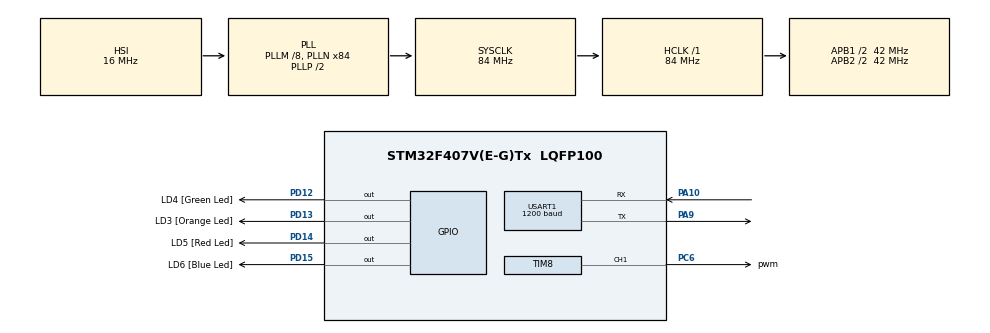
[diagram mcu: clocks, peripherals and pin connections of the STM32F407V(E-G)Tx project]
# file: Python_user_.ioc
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Mcu.Family=STM32F4
Mcu.Name=STM32F407V(E-G)Tx
Mcu.Package=LQFP100
NVIC.PriorityGroup=NVIC_PRIORITYGROUP_0
NVIC.USART1_IRQn=true\:0\:0\:false\:false\:true\:true\:true\:true
PA10.Mode=Asynchronous
PA10.Signal=USART1_RX
PA9.Mode=Asynchronous
PA9.Signal=USART1_TX
PC6.GPIO_Label=pwm
PC6.Signal=S_TIM8_CH1
PD12.GPIO_Label=LD4 [Green Led]
PD12.GPIO_PuPd=GPIO_NOPULL
PD12.GPIO_Speed=GPIO_SPEED_FREQ_LOW
PD12.Signal=GPIO_Output
PD13.GPIO_Label=LD3 [Orange Led]
PD13.GPIO_PuPd=GPIO_NOPULL
PD13.GPIO_Speed=GPIO_SPEED_FREQ_LOW
PD13.Signal=GPIO_Output
PD14.GPIO_Label=LD5 [Red Led]
PD14.GPIO_PuPd=GPIO_NOPULL
PD14.GPIO_Speed=GPIO_SPEED_FREQ_LOW
PD14.Signal=GPIO_Output
PD15.GPIO_Label=LD6 [Blue Led]
PD15.GPIO_PuPd=GPIO_NOPULL
PD15.GPIO_Speed=GPIO_SPEED_FREQ_LOW
PD15.Signal=GPIO_Output
ProjectManager.HeapSize=0x200
ProjectManager.StackSize=0x400
ProjectManager.TargetToolchain=STM32CubeIDE
RCC.48MHZClocksFreq_Value=24000000
RCC.AHBFreq_Value=84000000
RCC.APB1CLKDivider=RCC_HCLK_DIV2
RCC.APB1Freq_Value=42000000
RCC.APB1TimFreq_Value=84000000
RCC.APB2CLKDivider=RCC_HCLK_DIV2
RCC.APB2Freq_Value=42000000
RCC.APB2TimFreq_Value=84000000
RCC.CortexFreq_Value=84000000
RCC.HCLKFreq_Value=84000000
RCC.HSE_VALUE=8000000
RCC.HSI_VALUE=16000000
RCC.LSE_VALUE=32768
RCC.PLLM=8
RCC.PLLN=84
RCC.PLLQ=7
RCC.SYSCLKFreq_VALUE=84000000
RCC.SYSCLKSource=RCC_SYSCLKSOURCE_PLLCLK
RCC.VCOOutputFreq_Value=168000000
SH.S_TIM8_CH1.0=TIM8_CH1,PWM Generation1 CH1
TIM1.Period=65535-1
TIM1.Prescaler=839
TIM8.AutoReloadPreload=TIM_AUTORELOAD_PRELOAD_ENABLE
TIM8.Channel-PWM\ Generation1\ CH1=TIM_CHANNEL_1
TIM8.Period=9999
TIM8.Prescaler=167
USART1.BaudRate=1200
USART1.VirtualMode=VM_ASYNC
VP_TIM1_VS_ClockSourceINT.Mode=Internal
VP_TIM8_VS_ClockSourceINT.Mode=Internal
board=STM32F407G-DISC1

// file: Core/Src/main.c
/* USER CODE BEGIN Header */
/**
  ******************************************************************************
  * @file           : main.c
  * @brief          : Main program body
  ******************************************************************************
  * @attention
  *
  * Copyright (c) 2022 STMicroelectronics.
  * All rights reserved.
  *
  * This software is licensed under terms that can be found in the LICENSE file
  * in the root directory of this software component.
  * If no LICENSE file comes with this software, it is provided AS-IS.
  *
  ******************************************************************************
  */
/* USER CODE END Header */
#include "main.h"
#include "led_driver.h"
#include "string.h"

TIM_HandleTypeDef htim1;
TIM_HandleTypeDef htim8;

UART_HandleTypeDef huart1;

void SystemClock_Config(void);
static void MX_GPIO_Init(void);
static void MX_TIM8_Init(void);
static void MX_USART1_UART_Init(void);
static void MX_TIM1_Init(void);
/* USER CODE BEGIN PFP */
void Pyqt_led_app(uint8_t *data);
/* USER CODE END PFP */

/* USER CODE BEGIN 0 */
uint8_t gdata[3];

/* USER CODE END 0 */

int main(void)
{

  /* MCU Configuration--------------------------------------------------------*/

  /* Reset of all peripherals, Initializes the Flash interface and the Systick. */
  HAL_Init();

  /* Configure the system clock */
  SystemClock_Config();

  /* Initialize all configured peripherals */
  MX_GPIO_Init();
  MX_TIM8_Init();
  MX_USART1_UART_Init();
  MX_TIM1_Init();
  /* USER CODE BEGIN 2 */

HAL_UART_Receive_IT(&huart1, (uint8_t*)gdata,2);

HAL_TIM_PWM_Start(&htim8,TIM_CHANNEL_1);

  /* USER CODE END 2 */

  /* Infinite loop */
  /* USER CODE BEGIN WHILE */
  while (1)
  {

	  LED_Apps(gdata);                               //

	 HAL_UART_Receive_IT(&huart1,(uint8_t*)gdata,2); //

    /* USER CODE END WHILE */

  }
}

void SystemClock_Config(void)
{
  RCC_OscInitTypeDef RCC_OscInitStruct = {0};
  RCC_ClkInitTypeDef RCC_ClkInitStruct = {0};

  /** Configure the main internal regulator output voltage
  */
  __HAL_RCC_PWR_CLK_ENABLE();
  __HAL_PWR_VOLTAGESCALING_CONFIG(PWR_REGULATOR_VOLTAGE_SCALE1);

  /** Initializes the RCC Oscillators according to the specified parameters
  * in the RCC_OscInitTypeDef structure.
  */
  RCC_OscInitStruct.OscillatorType = RCC_OSCILLATORTYPE_HSI;
  RCC_OscInitStruct.HSIState = RCC_HSI_ON;
  RCC_OscInitStruct.HSICalibrationValue = RCC_HSICALIBRATION_DEFAULT;
  RCC_OscInitStruct.PLL.PLLState = RCC_PLL_ON;
  RCC_OscInitStruct.PLL.PLLSource = RCC_PLLSOURCE_HSI;
  RCC_OscInitStruct.PLL.PLLM = 8;
  RCC_OscInitStruct.PLL.PLLN = 84;
  RCC_OscInitStruct.PLL.PLLP = RCC_PLLP_DIV2;
  RCC_OscInitStruct.PLL.PLLQ = 7;
  if (HAL_RCC_OscConfig(&RCC_OscInitStruct) != HAL_OK)
  {
    Error_Handler();
  }

  /** Initializes the CPU, AHB and APB buses clocks
  */
  RCC_ClkInitStruct.ClockType = RCC_CLOCKTYPE_HCLK|RCC_CLOCKTYPE_SYSCLK
                              |RCC_CLOCKTYPE_PCLK1|RCC_CLOCKTYPE_PCLK2;
  RCC_ClkInitStruct.SYSCLKSource = RCC_SYSCLKSOURCE_PLLCLK;
  RCC_ClkInitStruct.AHBCLKDivider = RCC_SYSCLK_DIV1;
  RCC_ClkInitStruct.APB1CLKDivider = RCC_HCLK_DIV2;
  RCC_ClkInitStruct.APB2CLKDivider = RCC_HCLK_DIV2;

  if (HAL_RCC_ClockConfig(&RCC_ClkInitStruct, FLASH_LATENCY_2) != HAL_OK)
  {
    Error_Handler();
  }
}

static void MX_TIM1_Init(void)
{

  TIM_ClockConfigTypeDef sClockSourceConfig = {0};
  TIM_MasterConfigTypeDef sMasterConfig = {0};

  htim1.Instance = TIM1;
  htim1.Init.Prescaler = 839;
  htim1.Init.CounterMode = TIM_COUNTERMODE_UP;
  htim1.Init.Period = 65535-1;
  htim1.Init.ClockDivision = TIM_CLOCKDIVISION_DIV1;
  htim1.Init.RepetitionCounter = 0;
  htim1.Init.AutoReloadPreload = TIM_AUTORELOAD_PRELOAD_DISABLE;
  if (HAL_TIM_Base_Init(&htim1) != HAL_OK)
  {
    Error_Handler();
  }
  sClockSourceConfig.ClockSource = TIM_CLOCKSOURCE_INTERNAL;
  if (HAL_TIM_ConfigClockSource(&htim1, &sClockSourceConfig) != HAL_OK)
  {
    Error_Handler();
  }
  sMasterConfig.MasterOutputTrigger = TIM_TRGO_RESET;
  sMasterConfig.MasterSlaveMode = TIM_MASTERSLAVEMODE_DISABLE;
  if (HAL_TIMEx_MasterConfigSynchronization(&htim1, &sMasterConfig) != HAL_OK)
  {
    Error_Handler();
  }

}

static void MX_TIM8_Init(void)
{

  TIM_ClockConfigTypeDef sClockSourceConfig = {0};
  TIM_MasterConfigTypeDef sMasterConfig = {0};
  TIM_OC_InitTypeDef sConfigOC = {0};
  TIM_BreakDeadTimeConfigTypeDef sBreakDeadTimeConfig = {0};

  htim8.Instance = TIM8;
  htim8.Init.Prescaler = 167;
  htim8.Init.CounterMode = TIM_COUNTERMODE_UP;
  htim8.Init.Period = 9999;
  htim8.Init.ClockDivision = TIM_CLOCKDIVISION_DIV1;
  htim8.Init.RepetitionCounter = 0;
  htim8.Init.AutoReloadPreload = TIM_AUTORELOAD_PRELOAD_ENABLE;
  if (HAL_TIM_Base_Init(&htim8) != HAL_OK)
  {
    Error_Handler();
  }
  sClockSourceConfig.ClockSource = TIM_CLOCKSOURCE_INTERNAL;
  if (HAL_TIM_ConfigClockSource(&htim8, &sClockSourceConfig) != HAL_OK)
  {
    Error_Handler();
  }
  if (HAL_TIM_PWM_Init(&htim8) != HAL_OK)
  {
    Error_Handler();
  }
  sMasterConfig.MasterOutputTrigger = TIM_TRGO_RESET;
  sMasterConfig.MasterSlaveMode = TIM_MASTERSLAVEMODE_DISABLE;
  if (HAL_TIMEx_MasterConfigSynchronization(&htim8, &sMasterConfig) != HAL_OK)
  {
    Error_Handler();
  }
  sConfigOC.OCMode = TIM_OCMODE_PWM1;
  sConfigOC.Pulse = 0;
  sConfigOC.OCPolarity = TIM_OCPOLARITY_HIGH;
  sConfigOC.OCNPolarity = TIM_OCNPOLARITY_HIGH;
  sConfigOC.OCFastMode = TIM_OCFAST_DISABLE;
  sConfigOC.OCIdleState = TIM_OCIDLESTATE_RESET;
  sConfigOC.OCNIdleState = TIM_OCNIDLESTATE_RESET;
  if (HAL_TIM_PWM_ConfigChannel(&htim8, &sConfigOC, TIM_CHANNEL_1) != HAL_OK)
  {
    Error_Handler();
  }
  sBreakDeadTimeConfig.OffStateRunMode = TIM_OSSR_DISABLE;
  sBreakDeadTimeConfig.OffStateIDLEMode = TIM_OSSI_DISABLE;
  sBreakDeadTimeConfig.LockLevel = TIM_LOCKLEVEL_OFF;
  sBreakDeadTimeConfig.DeadTime = 0;
  sBreakDeadTimeConfig.BreakState = TIM_BREAK_DISABLE;
  sBreakDeadTimeConfig.BreakPolarity = TIM_BREAKPOLARITY_HIGH;
  sBreakDeadTimeConfig.AutomaticOutput = TIM_AUTOMATICOUTPUT_DISABLE;
  if (HAL_TIMEx_ConfigBreakDeadTime(&htim8, &sBreakDeadTimeConfig) != HAL_OK)
  {
    Error_Handler();
  }
  HAL_TIM_MspPostInit(&htim8);

}

static void MX_USART1_UART_Init(void)
{

  huart1.Instance = USART1;
  huart1.Init.BaudRate = 1200;
  huart1.Init.WordLength = UART_WORDLENGTH_8B;
  huart1.Init.StopBits = UART_STOPBITS_1;
  huart1.Init.Parity = UART_PARITY_NONE;
  huart1.Init.Mode = UART_MODE_TX_RX;
  huart1.Init.HwFlowCtl = UART_HWCONTROL_NONE;
  huart1.Init.OverSampling = UART_OVERSAMPLING_16;
  if (HAL_UART_Init(&huart1) != HAL_OK)
  {
    Error_Handler();
  }
  /* USER CODE BEGIN USART1_Init 2 */
  HAL_NVIC_SetPriority(USART1_IRQn  , 0, 0);
  HAL_NVIC_EnableIRQ(USART1_IRQn);
  /* USER CODE END USART1_Init 2 */

}

static void MX_GPIO_Init(void)
{
  GPIO_InitTypeDef GPIO_InitStruct = {0};

  /* GPIO Ports Clock Enable */
  __HAL_RCC_GPIOD_CLK_ENABLE();
  __HAL_RCC_GPIOC_CLK_ENABLE();
  __HAL_RCC_GPIOA_CLK_ENABLE();

  /*Configure GPIO pin Output Level */
  HAL_GPIO_WritePin(GPIOD, LD4_Pin|LD3_Pin|LD5_Pin|LD6_Pin, GPIO_PIN_RESET);

  /*Configure GPIO pins : LD4_Pin LD3_Pin LD5_Pin LD6_Pin */
  GPIO_InitStruct.Pin = LD4_Pin|LD3_Pin|LD5_Pin|LD6_Pin;
  GPIO_InitStruct.Mode = GPIO_MODE_OUTPUT_PP;
  GPIO_InitStruct.Pull = GPIO_NOPULL;
  GPIO_InitStruct.Speed = GPIO_SPEED_FREQ_LOW;
  HAL_GPIO_Init(GPIOD, &GPIO_InitStruct);

}

/* USER CODE BEGIN 4 */

/*
 * It is the part where the task to be done with interrupt is located.
 * @param *data  is the data coming to the interrupt
 * */

void USART1_IRQHandler(const uint8_t * data )
{
  /* USER CODE BEGIN USART1_IRQn 0 */
	 HAL_GPIO_WritePin(GPIOD, GPIO_PIN_12 | GPIO_PIN_13|GPIO_PIN_14 | GPIO_PIN_15, GPIO_PIN_RESET);

    if((data[0] == '5') ){
	TIM8->CCR1 = 450 + ((data[1])* 4U); /*--> Servo motor angel control parameter<--*/
    }

	/* USER CODE END USART1_IRQn 0 */
  HAL_UART_IRQHandler(&huart1);

  /* USER CODE BEGIN USART1_IRQn 1 */

  /* USER CODE END USART1_IRQn 1 */
}
/* USER CODE END 4 */

void Error_Handler(void)
{
  __disable_irq();
  while (1)
  {
  }
}
